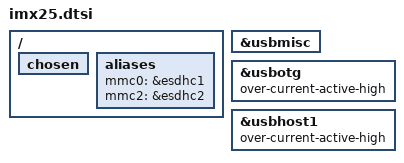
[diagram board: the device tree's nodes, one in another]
/*
 * Copyright 2012 Sascha Hauer, Pengutronix <s.hauer@pengutronix.de>
 *
 * The code contained herein is licensed under the GNU General Public
 * License. You may obtain a copy of the GNU General Public License
 * Version 2 or later at the following locations:
 *
 * http://www.opensource.org/licenses/gpl-license.html
 * http://www.gnu.org/copyleft/gpl.html
 */

/ {
	#address-cells = <1>;
	#size-cells = <1>;

	chosen { };

	aliases {
		mmc0 = &esdhc1;
		mmc2 = &esdhc2;
	};
};

&usbmisc {
	status = "okay";
};

&usbotg {
	over-current-active-high;
};

&usbhost1 {
	over-current-active-high;
};
